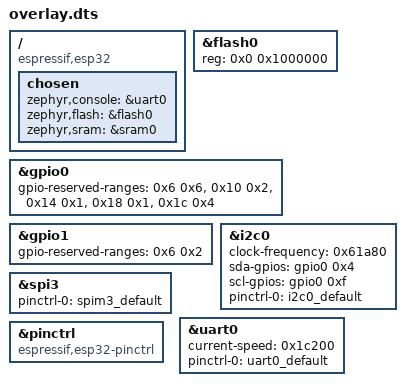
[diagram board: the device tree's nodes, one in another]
/ {
	compatible = "espressif,esp32", "hardkernel,odroid_go";
	chosen {
		zephyr,console = &uart0;
		zephyr,flash = &flash0;
		zephyr,sram = &sram0;
	};
};
&flash0{
	reg = < 0x0 0x1000000 >;
	status = "okay";
};
&gpio0{
	gpio-reserved-ranges = < 0x6 0x6 >, < 0x10 0x2 >, < 0x14 0x1 >, < 0x18 0x1 >, < 0x1c 0x4 >;
	status = "okay";
};
&gpio1{
	gpio-reserved-ranges = < 0x6 0x2 >;
	status = "okay";
};
&i2c0{
	status = "okay";
	clock-frequency = < 0x61a80 >;
	sda-gpios = < &gpio0 0x4 0x6 >;
	scl-gpios = < &gpio0 0xf 0x6 >;
	pinctrl-0 = < &i2c0_default >;
	pinctrl-names = "default";
};
&spi3{
	status = "okay";
	#address-cells = < 0x1 >;
	#size-cells = < 0x0 >;
	pinctrl-0 = < &spim3_default >;
	pinctrl-names = "default";
};
&uart0{
	status = "okay";
	current-speed = < 0x1c200 >;
	pinctrl-0 = < &uart0_default >;
	pinctrl-names = "default";
};
&pinctrl{
	compatible = "espressif,esp32-pinctrl";
	status = "okay";
};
